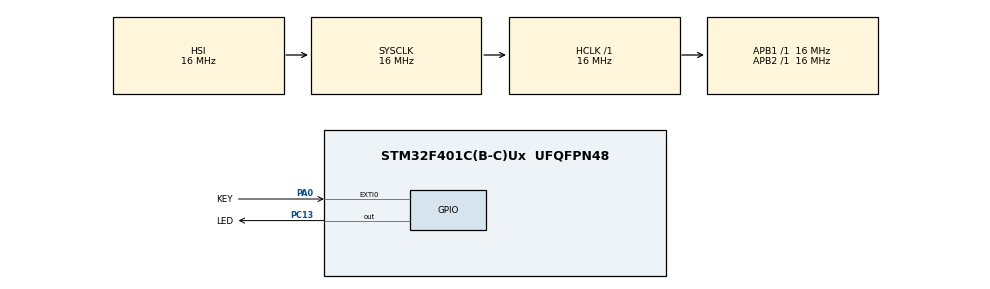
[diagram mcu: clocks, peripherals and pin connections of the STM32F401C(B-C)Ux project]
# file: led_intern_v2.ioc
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Mcu.Family=STM32F4
Mcu.Name=STM32F401C(B-C)Ux
Mcu.Package=UFQFPN48
NVIC.EXTI0_IRQn=true\:0\:0\:false\:false\:true\:true\:true\:true
NVIC.PriorityGroup=NVIC_PRIORITYGROUP_4
NVIC.TIM2_IRQn=true\:0\:0\:false\:false\:true\:true\:true\:true
PA0-WKUP.GPIO_Label=KEY
PA0-WKUP.GPIO_ModeDefaultEXTI=GPIO_MODE_IT_FALLING
PA0-WKUP.GPIO_PuPd=GPIO_PULLUP
PA0-WKUP.Signal=GPXTI0
PC13-ANTI_TAMP.GPIO_Label=LED
PC13-ANTI_TAMP.PinState=GPIO_PIN_SET
PC13-ANTI_TAMP.Signal=GPIO_Output
ProjectManager.HeapSize=0x200
ProjectManager.StackSize=0x400
ProjectManager.TargetToolchain=STM32CubeIDE
RCC.AHBFreq_Value=16000000
RCC.APB1Freq_Value=16000000
RCC.APB2Freq_Value=16000000
RCC.CortexFreq_Value=16000000
RCC.HSE_VALUE=25000000
RCC.HSI_VALUE=16000000
RCC.LSE_VALUE=32768
RCC.SYSCLKFreq_VALUE=16000000
RCC.VCOOutputFreq_Value=192000000
TIM2.Period=99
TIM2.Prescaler=15
VP_TIM2_VS_ClockSourceINT.Mode=Internal
board=custom

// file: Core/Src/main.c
/* USER CODE BEGIN Header */
/**
  ******************************************************************************
  * @file           : main.c
  * @brief          : Main program body
  ******************************************************************************
  * @attention
  *
  * Copyright (c) 2026 STMicroelectronics.
  * All rights reserved.
  *
  * This software is licensed under terms that can be found in the LICENSE file
  * in the root directory of this software component.
  * If no LICENSE file comes with this software, it is provided AS-IS.
  *
  ******************************************************************************
  */
/* USER CODE END Header */
#include "main.h"

/* USER CODE BEGIN PTD */

typedef enum
{
  LED_STATE_OFF = 0,
  LED_STATE_LOW_FADE,
  LED_STATE_MID_FADE,
  LED_STATE_HIGH_FADE
} LedState_t;

/* USER CODE END PTD */

TIM_HandleTypeDef htim2;

/* USER CODE BEGIN PV */

/* Buton ile degistirilen mevcut durum */
volatile LedState_t led_state = LED_STATE_OFF;

/* PWM icin faz sayaci (0-99 arasi doner) */
volatile uint8_t pwm_phase = 0;

/* LED parlakligi: 0 = sonuk, 100 = tam parlak */
volatile uint8_t brightness = 0;

/* 1 ise parlaklik artiyor, 0 ise azaliyor */
volatile uint8_t fade_up = 1;

/* Parlaklik kademesini yavaslatmak icin sayac */
volatile uint16_t fade_counter = 0;

/* USER CODE END PV */

void SystemClock_Config(void);
static void MX_GPIO_Init(void);
static void MX_TIM2_Init(void);

int main(void)
{

  /* MCU Configuration--------------------------------------------------------*/

  /* Reset of all peripherals, Initializes the Flash interface and the Systick. */
  HAL_Init();

  /* Configure the system clock */
  SystemClock_Config();

  /* Initialize all configured peripherals */
  MX_GPIO_Init();
  MX_TIM2_Init();
  /* USER CODE BEGIN 2 */

  /* TIM2'yi kesme uretecek sekilde baslat (100us'de bir PWM guncellenir) */
  if (HAL_TIM_Base_Start_IT(&htim2) != HAL_OK)
  {
    Error_Handler();
  }

  /* USER CODE END 2 */

  /* Infinite loop */
  while (1)
  {

  }
}

void SystemClock_Config(void)
{
  RCC_OscInitTypeDef RCC_OscInitStruct = {0};
  RCC_ClkInitTypeDef RCC_ClkInitStruct = {0};

  /** Configure the main internal regulator output voltage
  */
  __HAL_RCC_PWR_CLK_ENABLE();
  __HAL_PWR_VOLTAGESCALING_CONFIG(PWR_REGULATOR_VOLTAGE_SCALE2);

  /** Initializes the RCC Oscillators according to the specified parameters
  * in the RCC_OscInitTypeDef structure.
  */
  RCC_OscInitStruct.OscillatorType = RCC_OSCILLATORTYPE_HSI;
  RCC_OscInitStruct.HSIState = RCC_HSI_ON;
  RCC_OscInitStruct.HSICalibrationValue = RCC_HSICALIBRATION_DEFAULT;
  RCC_OscInitStruct.PLL.PLLState = RCC_PLL_NONE;
  if (HAL_RCC_OscConfig(&RCC_OscInitStruct) != HAL_OK)
  {
    Error_Handler();
  }

  /** Initializes the CPU, AHB and APB buses clocks
  */
  RCC_ClkInitStruct.ClockType = RCC_CLOCKTYPE_HCLK|RCC_CLOCKTYPE_SYSCLK
                              |RCC_CLOCKTYPE_PCLK1|RCC_CLOCKTYPE_PCLK2;
  RCC_ClkInitStruct.SYSCLKSource = RCC_SYSCLKSOURCE_HSI;
  RCC_ClkInitStruct.AHBCLKDivider = RCC_SYSCLK_DIV1;
  RCC_ClkInitStruct.APB1CLKDivider = RCC_HCLK_DIV1;
  RCC_ClkInitStruct.APB2CLKDivider = RCC_HCLK_DIV1;

  if (HAL_RCC_ClockConfig(&RCC_ClkInitStruct, FLASH_LATENCY_0) != HAL_OK)
  {
    Error_Handler();
  }
}

static void MX_TIM2_Init(void)
{

  TIM_ClockConfigTypeDef sClockSourceConfig = {0};
  TIM_MasterConfigTypeDef sMasterConfig = {0};

  htim2.Instance = TIM2;
  htim2.Init.Prescaler = 15;
  htim2.Init.CounterMode = TIM_COUNTERMODE_UP;
  htim2.Init.Period = 99;
  htim2.Init.ClockDivision = TIM_CLOCKDIVISION_DIV1;
  htim2.Init.AutoReloadPreload = TIM_AUTORELOAD_PRELOAD_DISABLE;
  if (HAL_TIM_Base_Init(&htim2) != HAL_OK)
  {
    Error_Handler();
  }
  sClockSourceConfig.ClockSource = TIM_CLOCKSOURCE_INTERNAL;
  if (HAL_TIM_ConfigClockSource(&htim2, &sClockSourceConfig) != HAL_OK)
  {
    Error_Handler();
  }
  sMasterConfig.MasterOutputTrigger = TIM_TRGO_RESET;
  sMasterConfig.MasterSlaveMode = TIM_MASTERSLAVEMODE_DISABLE;
  if (HAL_TIMEx_MasterConfigSynchronization(&htim2, &sMasterConfig) != HAL_OK)
  {
    Error_Handler();
  }

}

static void MX_GPIO_Init(void)
{
  GPIO_InitTypeDef GPIO_InitStruct = {0};

  /* GPIO Ports Clock Enable */
  __HAL_RCC_GPIOC_CLK_ENABLE();
  __HAL_RCC_GPIOA_CLK_ENABLE();

  /*Configure GPIO pin Output Level */
  HAL_GPIO_WritePin(LED_GPIO_Port, LED_Pin, GPIO_PIN_SET);

  /*Configure GPIO pin : LED_Pin */
  GPIO_InitStruct.Pin = LED_Pin;
  GPIO_InitStruct.Mode = GPIO_MODE_OUTPUT_PP;
  GPIO_InitStruct.Pull = GPIO_NOPULL;
  GPIO_InitStruct.Speed = GPIO_SPEED_FREQ_LOW;
  HAL_GPIO_Init(LED_GPIO_Port, &GPIO_InitStruct);

  /*Configure GPIO pin : KEY_Pin */
  GPIO_InitStruct.Pin = KEY_Pin;
  GPIO_InitStruct.Mode = GPIO_MODE_IT_FALLING;
  GPIO_InitStruct.Pull = GPIO_PULLUP;
  HAL_GPIO_Init(KEY_GPIO_Port, &GPIO_InitStruct);

  /* EXTI interrupt init*/
  HAL_NVIC_SetPriority(EXTI0_IRQn, 0, 0);
  HAL_NVIC_EnableIRQ(EXTI0_IRQn);

}

/* USER CODE BEGIN 4 */

/*
 * KEY butonu (PA0) basildiginda cagrilir.
 *
 * Debounce: buton kontaklari basilirken/birakilirken elektriksel
 * olarak birkac kez titresebilir (bounce), bu da tek basista
 * birden fazla kesme olusmasina yol acar. Art arda 200ms'den kisa
 * surede gelen kesmeleri yok sayarak bunu engelliyoruz.
 */
void HAL_GPIO_EXTI_Callback(uint16_t GPIO_Pin)
{
  static uint32_t last_tick = 0;
  uint32_t now = HAL_GetTick();

  if (GPIO_Pin != KEY_Pin)
  {
    return;
  }

  if ((now - last_tick) < 200)
  {
    return;
  }
  last_tick = now;

  switch (led_state)
  {
    case LED_STATE_OFF:
      led_state = LED_STATE_LOW_FADE;
      break;

    case LED_STATE_LOW_FADE:
      led_state = LED_STATE_MID_FADE;
      break;

    case LED_STATE_MID_FADE:
      led_state = LED_STATE_HIGH_FADE;
      break;

    case LED_STATE_HIGH_FADE:
      led_state = LED_STATE_OFF;
      brightness = 0;
      fade_up = 1;
      fade_counter = 0;
      break;
  }
}

/*
 * TIM2 her 100 mikrosaniyede bir cagrilir (10 kHz).
 *
 * led_state'e gore nefes alma hizini belirler, brightness'i
 * o hiza gore yukari/asagi kaydirir, ardindan PC13 uzerinde
 * yazilimsal PWM uretir.
 */
void HAL_TIM_PeriodElapsedCallback(TIM_HandleTypeDef *htim)
{
  uint16_t fade_step_ticks;

  if (htim->Instance != TIM2)
  {
    return;
  }

  if (led_state == LED_STATE_OFF)
  {
    brightness = 0;
  }
  else
  {
    /*
     * fade_step_ticks: brightness bir kademe (1) degismeden
     * once kac tane 100us'lik kesme beklenecegini belirler.
     * Deger kucukse hizli, buyukse yavas nefes alir.
     */
    switch (led_state)
    {
      case LED_STATE_LOW_FADE:
        fade_step_ticks = 600;  /* yavas: ~16s'de tam dongu */
        break;

      case LED_STATE_HIGH_FADE:
        fade_step_ticks = 20;  /* hizli: ~3s'de tam dongu */
        break;

      case LED_STATE_MID_FADE:
      default:
        fade_step_ticks = 300;  /* normal: ~8s'de tam dongu */
        break;
    }

    fade_counter++;
    if (fade_counter >= fade_step_ticks)
    {
      fade_counter = 0;

      if (fade_up)
      {
        if (brightness < 100)
        {
          brightness++;
        }
        else
        {
          fade_up = 0;
        }
      }
      else
      {
        if (brightness > 0)
        {
          brightness--;
        }
        else
        {
          fade_up = 1;
        }
      }
    }
  }

  pwm_phase++;
  if (pwm_phase >= 100)
  {
    pwm_phase = 0;
  }

  /* PC13 aktif-low: RESET = LED yanar, SET = LED soner */
  if (pwm_phase < brightness)
  {
    HAL_GPIO_WritePin(LED_GPIO_Port, LED_Pin, GPIO_PIN_RESET);
  }
  else
  {
    HAL_GPIO_WritePin(LED_GPIO_Port, LED_Pin, GPIO_PIN_SET);
  }
}

/* USER CODE END 4 */

void Error_Handler(void)
{
  __disable_irq();
  while (1)
  {
  }
}
